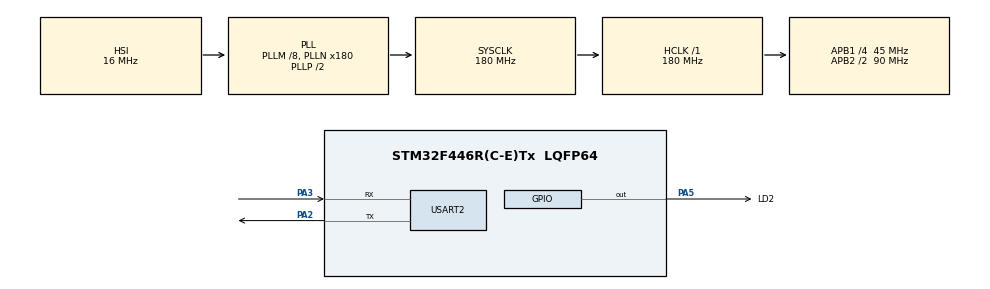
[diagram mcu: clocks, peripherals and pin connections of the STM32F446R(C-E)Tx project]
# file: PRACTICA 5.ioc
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Mcu.Family=STM32F4
Mcu.Name=STM32F446R(C-E)Tx
Mcu.Package=LQFP64
NVIC.PriorityGroup=NVIC_PRIORITYGROUP_4
PA2.Mode=Asynchronous
PA2.Signal=USART2_TX
PA3.Mode=Asynchronous
PA3.Signal=USART2_RX
PA5.GPIO_Label=LD2
PA5.Signal=GPIO_Output
ProjectManager.HeapSize=0x200
ProjectManager.StackSize=0x400
ProjectManager.TargetToolchain=STM32CubeIDE
RCC.AHBFreq_Value=180000000
RCC.APB1CLKDivider=RCC_HCLK_DIV4
RCC.APB1Freq_Value=45000000
RCC.APB1TimFreq_Value=90000000
RCC.APB2CLKDivider=RCC_HCLK_DIV2
RCC.APB2Freq_Value=90000000
RCC.APB2TimFreq_Value=180000000
RCC.CortexFreq_Value=180000000
RCC.HCLKFreq_Value=180000000
RCC.PLLM=8
RCC.PLLN=180
RCC.SYSCLKFreq_VALUE=180000000
RCC.SYSCLKSource=RCC_SYSCLKSOURCE_PLLCLK
RCC.USBFreq_Value=180000000
RCC.VCOOutputFreq_Value=360000000
USART2.VirtualMode=VM_ASYNC
board=custom

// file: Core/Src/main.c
/* USER CODE BEGIN Header */
/**
  ******************************************************************************
  * @file           : main.c
  * @brief          : Main program body con integración de Práctica 5
  ******************************************************************************
  */
/* USER CODE END Header */

#include "main.h"
#include "usart.h"
#include "gpio.h"

/* USER CODE BEGIN Includes */
#include "API_uart.h"
#include "API_cmdparser.h"
#include "API_debounce.h"
/* USER CODE END Includes */

void SystemClock_Config(void);

int main(void)
{
  /* MCU Configuration--------------------------------------------------------*/

  /* Reset of all peripherals, Initializes the Flash interface and the Systick. */
  HAL_Init();

  /* Configure the system clock */
  SystemClock_Config();

  /* Initialize all configured peripherals */
  MX_GPIO_Init();
  MX_USART2_UART_Init();

  /* USER CODE BEGIN 2 */

  /* 1. Inicializar la UART (Imprimirá los parámetros en la terminal) */
  if (uartInit() == false) {
	  Error_Handler();
  }

  /* 2. Inicializar el Parser de comandos */
  cmdParserInit();

  /* 3. Inicializar el antirrebote del botón azul */
  debounceFSM_init();

  uartSendString((uint8_t*)"Sistema Listo. Escriba 'HELP' para ver comandos.\r\n");

  /* USER CODE END 2 */

  /* Infinite loop */
  /* USER CODE BEGIN WHILE */
  while (1)
  {
    /* 4. Refresco constante de la lógica del parser (No bloqueante) */
    cmdPoll();

    /* 5. Refresco constante del antirrebote */
    debounceFSM_update();

    /* 6. Interacción con el botón */
    if (readKey()) {
    	uartSendString((uint8_t*)"Botón B1 presionado\r\n");
    }

    /* USER CODE END WHILE */

  }
}

void SystemClock_Config(void)
{
  RCC_OscInitTypeDef RCC_OscInitStruct = {0};
  RCC_ClkInitTypeDef RCC_ClkInitStruct = {0};

  __HAL_RCC_PWR_CLK_ENABLE();
  __HAL_PWR_VOLTAGESCALING_CONFIG(PWR_REGULATOR_VOLTAGE_SCALE1);

  RCC_OscInitStruct.OscillatorType = RCC_OSCILLATORTYPE_HSI;
  RCC_OscInitStruct.HSIState = RCC_HSI_ON;
  RCC_OscInitStruct.HSICalibrationValue = RCC_HSICALIBRATION_DEFAULT;
  RCC_OscInitStruct.PLL.PLLState = RCC_PLL_ON;
  RCC_OscInitStruct.PLL.PLLSource = RCC_PLLSOURCE_HSI;
  RCC_OscInitStruct.PLL.PLLM = 8;
  RCC_OscInitStruct.PLL.PLLN = 180;
  RCC_OscInitStruct.PLL.PLLP = RCC_PLLP_DIV2;
  RCC_OscInitStruct.PLL.PLLQ = 2;
  RCC_OscInitStruct.PLL.PLLR = 2;
  if (HAL_RCC_OscConfig(&RCC_OscInitStruct) != HAL_OK)
  {
    Error_Handler();
  }

  if (HAL_PWREx_EnableOverDrive() != HAL_OK)
  {
    Error_Handler();
  }

  RCC_ClkInitStruct.ClockType = RCC_CLOCKTYPE_HCLK|RCC_CLOCKTYPE_SYSCLK
                              |RCC_CLOCKTYPE_PCLK1|RCC_CLOCKTYPE_PCLK2;
  RCC_ClkInitStruct.SYSCLKSource = RCC_SYSCLKSOURCE_PLLCLK;
  RCC_ClkInitStruct.AHBCLKDivider = RCC_SYSCLK_DIV1;
  RCC_ClkInitStruct.APB1CLKDivider = RCC_HCLK_DIV4;
  RCC_ClkInitStruct.APB2CLKDivider = RCC_HCLK_DIV2;

  if (HAL_RCC_ClockConfig(&RCC_ClkInitStruct, FLASH_LATENCY_5) != HAL_OK)
  {
    Error_Handler();
  }
}

/* USER CODE BEGIN 4 */
/**
  * @brief  This function is executed in case of error occurrence.
  * @retval None
  */
void Error_Handler(void)
{
  /* USER CODE BEGIN Error_Handler_Debug */
  __disable_irq();
  while (1)
  {
  }
  /* USER CODE END Error_Handler_Debug */
}

#ifdef  USE_FULL_ASSERT
void assert_failed(uint8_t *file, uint32_t line)
{
}
#endif /* USE_FULL_ASSERT */
/* USER CODE END 4 */
